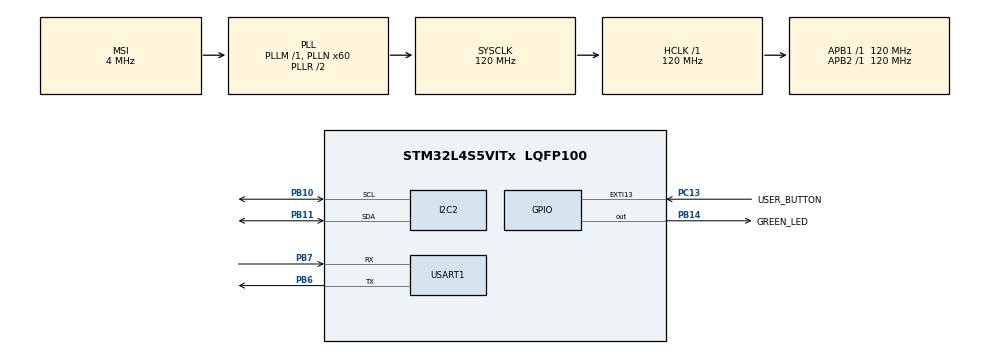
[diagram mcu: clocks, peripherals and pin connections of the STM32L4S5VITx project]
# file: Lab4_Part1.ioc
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Mcu.Family=STM32L4
RCC.MSI_VALUE=4000000
RCC.CortexFreq_Value=120000000
PB10.Mode=I2C
PC13.Signal=GPXTI13
PB14.GPIO_Label=GREEN_LED
I2C2.Timing=0x307075B1
PC13.GPIO_Label=USER_BUTTON
PB11.Signal=I2C2_SDA
RCC.SYSCLKSource=RCC_SYSCLKSOURCE_PLLCLK
ProjectManager.StackSize=0x400
USART1.VirtualMode-Asynchronous=VM_ASYNC
PB11.Mode=I2C
PB3\ (JTDO/TRACESWO).Signal=SYS_JTDO-SWO
ProjectManager.TargetToolchain=STM32CubeIDE
RCC.HCLKFreq_Value=120000000
RCC.APB2TimFreq_Value=120000000
PB6.Signal=USART1_TX
PB6.Mode=Asynchronous
RCC.USBFreq_Value=48000000
RCC.AHBFreq_Value=120000000
PB10.Signal=I2C2_SCL
PB14.Signal=GPIO_Output
RCC.HSE_VALUE=8000000
board=B-L4S5I-IOT01A
RCC.VCOOutputFreq_Value=240000000
RCC.APB2Freq_Value=120000000
VP_TIM2_VS_ClockSourceINT.Mode=Internal
RCC.ADCFreq_Value=48000000
PB7.Signal=USART1_RX
TIM2.Period=12000000
Mcu.Name=STM32L4S5VITx
RCC.SYSCLKFreq_VALUE=120000000
Mcu.Package=LQFP100
PB7.Mode=Asynchronous
ProjectManager.HeapSize=0x200
RCC.HSI_VALUE=16000000
NVIC.PriorityGroup=NVIC_PRIORITYGROUP_4
RCC.PLLN=60
RCC.APB1TimFreq_Value=120000000
RCC.APB1Freq_Value=120000000
RCC.HSI48_VALUE=48000000
PA13\ (JTMS/SWDIO).Signal=SYS_JTMS-SWDIO
RCC.PLLSAI1N=24

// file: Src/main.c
/* USER CODE BEGIN Header */
/**
  ******************************************************************************
  * @file           : main.c
  * @brief          : Main program body
  ******************************************************************************
  * @attention
  *
  * <h2><center>&copy; Copyright (c) 2021 STMicroelectronics.
  * All rights reserved.</center></h2>
  *
  * This software component is licensed by ST under BSD 3-Clause license,
  * the "License"; You may not use this file except in compliance with the
  * License. You may obtain a copy of the License at:
  *                        opensource.org/licenses/BSD-3-Clause
  *
  ******************************************************************************
  */
/* USER CODE END Header */
#include "main.h"

/* USER CODE BEGIN Includes */
#include <stdio.h>
#include <string.h>
#include "stm32l4s5i_iot01_accelero.h"
#include "stm32l4s5i_iot01_gyro.h"
#include "stm32l4s5i_iot01_hsensor.h"
#include "stm32l4s5i_iot01_magneto.h"
#include "stm32l4s5i_iot01_nfctag.h"
#include "stm32l4s5i_iot01_psensor.h"
#include "stm32l4s5i_iot01_tsensor.h"
/* USER CODE END Includes */

I2C_HandleTypeDef hi2c2;

TIM_HandleTypeDef htim2;

UART_HandleTypeDef huart1;

void SystemClock_Config(void);
static void MX_GPIO_Init(void);
static void MX_I2C2_Init(void);
static void MX_USART1_UART_Init(void);
static void MX_TIM2_Init(void);
/* USER CODE BEGIN PFP */
void HAL_GPIO_EXTI_Callback(uint16_t GPIO_Pin);
void HAL_TIM_PeriodElapsedCallback (TIM_HandleTypeDef * htim);
/* USER CODE END PFP */

/* USER CODE BEGIN 0 */
float humidity = 0.0;	// for humidity, HTS221
int16_t pDataXYZ_magneto[3];		// for magnetometer, LIS3MDL
int16_t pDataXYZ_accelero[3];		// for accelerometer, LSM6DSL
float pressure = 0;		// for barometer, LPS22HB

uint8_t str[100];		// store string
int button_counter = 0;	// count button state
int number = 0;			// for sample rate check
int another_number = 0;	// for sample rate check
/* USER CODE END 0 */

int main(void)
{

  /* MCU Configuration--------------------------------------------------------*/

  /* Reset of all peripherals, Initializes the Flash interface and the Systick. */
  HAL_Init();

  /* Configure the system clock */
  SystemClock_Config();

  /* Initialize all configured peripherals */
  MX_GPIO_Init();
  MX_I2C2_Init();
  MX_USART1_UART_Init();
  MX_TIM2_Init();
  /* USER CODE BEGIN 2 */
  // Initialize peripherals
  BSP_HSENSOR_Init();
  BSP_MAGNETO_Init();
  BSP_ACCELERO_Init();
  BSP_PSENSOR_Init();
  HAL_TIM_Base_Start_IT(&htim2);
  /* USER CODE END 2 */

  /* Infinite loop */
  /* USER CODE BEGIN WHILE */
  while (1)
  {
	  // Read value
	  humidity = BSP_HSENSOR_ReadHumidity();	// read humidity
	  BSP_MAGNETO_GetXYZ(pDataXYZ_magneto);		// read magneto
	  BSP_ACCELERO_AccGetXYZ(pDataXYZ_accelero);// read accelero
	  pressure = BSP_PSENSOR_ReadPressure();	// read pressure
	  another_number = number * 2;		// for sample rate testing in SWV timeline graph
	  HAL_Delay(10);	// further adjust sample rate
	  // Print value
	  memset(str,0,100);		// clear str
	  if (button_counter == 0) {
		  sprintf((char*)str, "The humidity reading is %d\n", (int)humidity);	// store string into str
		  HAL_UART_Transmit(&huart1, str, strlen((char*)str), 5);	// display humidity
	  }
	  else if (button_counter == 1) {
		  sprintf((char*)str, "The magnetometer readings are X = %d, Y = %d, Z = %d\n", (int)pDataXYZ_magneto[0], (int)pDataXYZ_magneto[1], (int)pDataXYZ_magneto[2]);	// store string into str
		  HAL_UART_Transmit(&huart1, str, strlen((char*)str), 5);	// display 3-axis magnetometer readings
	  }
	  else if (button_counter == 2) {
		  sprintf((char*)str, "The accelerometer readings are X = %d, Y = %d, Z = %d\n", (int)pDataXYZ_accelero[0], (int)pDataXYZ_accelero[1], (int)pDataXYZ_accelero[2]);	// store string into str
		  HAL_UART_Transmit(&huart1, str, strlen((char*)str), 5);	// display 3D accelerometer readings
	  }
	  else if (button_counter == 3) {
		  sprintf((char*)str, "The barometer reading is %d\n", (int)pressure);	// store string into str
		  HAL_UART_Transmit(&huart1, str, strlen((char*)str), 5);	// display pressure
	  }
    /* USER CODE END WHILE */

  }
}

void SystemClock_Config(void)
{
  RCC_OscInitTypeDef RCC_OscInitStruct = {0};
  RCC_ClkInitTypeDef RCC_ClkInitStruct = {0};
  RCC_PeriphCLKInitTypeDef PeriphClkInit = {0};

  /** Configure the main internal regulator output voltage
  */
  if (HAL_PWREx_ControlVoltageScaling(PWR_REGULATOR_VOLTAGE_SCALE1_BOOST) != HAL_OK)
  {
    Error_Handler();
  }
  /** Initializes the RCC Oscillators according to the specified parameters
  * in the RCC_OscInitTypeDef structure.
  */
  RCC_OscInitStruct.OscillatorType = RCC_OSCILLATORTYPE_MSI;
  RCC_OscInitStruct.MSIState = RCC_MSI_ON;
  RCC_OscInitStruct.MSICalibrationValue = 0;
  RCC_OscInitStruct.MSIClockRange = RCC_MSIRANGE_6;
  RCC_OscInitStruct.PLL.PLLState = RCC_PLL_ON;
  RCC_OscInitStruct.PLL.PLLSource = RCC_PLLSOURCE_MSI;
  RCC_OscInitStruct.PLL.PLLM = 1;
  RCC_OscInitStruct.PLL.PLLN = 60;
  RCC_OscInitStruct.PLL.PLLP = RCC_PLLP_DIV2;
  RCC_OscInitStruct.PLL.PLLQ = RCC_PLLQ_DIV2;
  RCC_OscInitStruct.PLL.PLLR = RCC_PLLR_DIV2;
  if (HAL_RCC_OscConfig(&RCC_OscInitStruct) != HAL_OK)
  {
    Error_Handler();
  }
  /** Initializes the CPU, AHB and APB buses clocks
  */
  RCC_ClkInitStruct.ClockType = RCC_CLOCKTYPE_HCLK|RCC_CLOCKTYPE_SYSCLK
                              |RCC_CLOCKTYPE_PCLK1|RCC_CLOCKTYPE_PCLK2;
  RCC_ClkInitStruct.SYSCLKSource = RCC_SYSCLKSOURCE_PLLCLK;
  RCC_ClkInitStruct.AHBCLKDivider = RCC_SYSCLK_DIV1;
  RCC_ClkInitStruct.APB1CLKDivider = RCC_HCLK_DIV1;
  RCC_ClkInitStruct.APB2CLKDivider = RCC_HCLK_DIV1;

  if (HAL_RCC_ClockConfig(&RCC_ClkInitStruct, FLASH_LATENCY_5) != HAL_OK)
  {
    Error_Handler();
  }
  PeriphClkInit.PeriphClockSelection = RCC_PERIPHCLK_USART1|RCC_PERIPHCLK_I2C2;
  PeriphClkInit.Usart1ClockSelection = RCC_USART1CLKSOURCE_PCLK2;
  PeriphClkInit.I2c2ClockSelection = RCC_I2C2CLKSOURCE_PCLK1;
  if (HAL_RCCEx_PeriphCLKConfig(&PeriphClkInit) != HAL_OK)
  {
    Error_Handler();
  }
}

static void MX_I2C2_Init(void)
{

  hi2c2.Instance = I2C2;
  hi2c2.Init.Timing = 0x307075B1;
  hi2c2.Init.OwnAddress1 = 0;
  hi2c2.Init.AddressingMode = I2C_ADDRESSINGMODE_7BIT;
  hi2c2.Init.DualAddressMode = I2C_DUALADDRESS_DISABLE;
  hi2c2.Init.OwnAddress2 = 0;
  hi2c2.Init.OwnAddress2Masks = I2C_OA2_NOMASK;
  hi2c2.Init.GeneralCallMode = I2C_GENERALCALL_DISABLE;
  hi2c2.Init.NoStretchMode = I2C_NOSTRETCH_DISABLE;
  if (HAL_I2C_Init(&hi2c2) != HAL_OK)
  {
    Error_Handler();
  }
  /** Configure Analogue filter
  */
  if (HAL_I2CEx_ConfigAnalogFilter(&hi2c2, I2C_ANALOGFILTER_ENABLE) != HAL_OK)
  {
    Error_Handler();
  }
  /** Configure Digital filter
  */
  if (HAL_I2CEx_ConfigDigitalFilter(&hi2c2, 0) != HAL_OK)
  {
    Error_Handler();
  }

}

static void MX_TIM2_Init(void)
{

  TIM_ClockConfigTypeDef sClockSourceConfig = {0};
  TIM_MasterConfigTypeDef sMasterConfig = {0};

  htim2.Instance = TIM2;
  htim2.Init.Prescaler = 0;
  htim2.Init.CounterMode = TIM_COUNTERMODE_UP;
  htim2.Init.Period = 12000000;
  htim2.Init.ClockDivision = TIM_CLOCKDIVISION_DIV1;
  htim2.Init.AutoReloadPreload = TIM_AUTORELOAD_PRELOAD_DISABLE;
  if (HAL_TIM_Base_Init(&htim2) != HAL_OK)
  {
    Error_Handler();
  }
  sClockSourceConfig.ClockSource = TIM_CLOCKSOURCE_INTERNAL;
  if (HAL_TIM_ConfigClockSource(&htim2, &sClockSourceConfig) != HAL_OK)
  {
    Error_Handler();
  }
  sMasterConfig.MasterOutputTrigger = TIM_TRGO_UPDATE;
  sMasterConfig.MasterSlaveMode = TIM_MASTERSLAVEMODE_DISABLE;
  if (HAL_TIMEx_MasterConfigSynchronization(&htim2, &sMasterConfig) != HAL_OK)
  {
    Error_Handler();
  }

}

static void MX_USART1_UART_Init(void)
{

  huart1.Instance = USART1;
  huart1.Init.BaudRate = 115200;
  huart1.Init.WordLength = UART_WORDLENGTH_8B;
  huart1.Init.StopBits = UART_STOPBITS_1;
  huart1.Init.Parity = UART_PARITY_NONE;
  huart1.Init.Mode = UART_MODE_TX_RX;
  huart1.Init.HwFlowCtl = UART_HWCONTROL_NONE;
  huart1.Init.OverSampling = UART_OVERSAMPLING_16;
  huart1.Init.OneBitSampling = UART_ONE_BIT_SAMPLE_DISABLE;
  huart1.Init.ClockPrescaler = UART_PRESCALER_DIV1;
  huart1.AdvancedInit.AdvFeatureInit = UART_ADVFEATURE_NO_INIT;
  if (HAL_UART_Init(&huart1) != HAL_OK)
  {
    Error_Handler();
  }
  if (HAL_UARTEx_SetTxFifoThreshold(&huart1, UART_TXFIFO_THRESHOLD_1_8) != HAL_OK)
  {
    Error_Handler();
  }
  if (HAL_UARTEx_SetRxFifoThreshold(&huart1, UART_RXFIFO_THRESHOLD_1_8) != HAL_OK)
  {
    Error_Handler();
  }
  if (HAL_UARTEx_DisableFifoMode(&huart1) != HAL_OK)
  {
    Error_Handler();
  }

}

static void MX_GPIO_Init(void)
{
  GPIO_InitTypeDef GPIO_InitStruct = {0};

  /* GPIO Ports Clock Enable */
  __HAL_RCC_GPIOE_CLK_ENABLE();
  __HAL_RCC_GPIOC_CLK_ENABLE();
  __HAL_RCC_GPIOB_CLK_ENABLE();
  __HAL_RCC_GPIOA_CLK_ENABLE();

  /*Configure GPIO pin Output Level */
  HAL_GPIO_WritePin(RED_LED_GPIO_Port, RED_LED_Pin, GPIO_PIN_RESET);

  /*Configure GPIO pin Output Level */
  HAL_GPIO_WritePin(GREEN_LED_GPIO_Port, GREEN_LED_Pin, GPIO_PIN_RESET);

  /*Configure GPIO pin : RED_LED_Pin */
  GPIO_InitStruct.Pin = RED_LED_Pin;
  GPIO_InitStruct.Mode = GPIO_MODE_OUTPUT_PP;
  GPIO_InitStruct.Pull = GPIO_NOPULL;
  GPIO_InitStruct.Speed = GPIO_SPEED_FREQ_LOW;
  HAL_GPIO_Init(RED_LED_GPIO_Port, &GPIO_InitStruct);

  /*Configure GPIO pin : USER_BUTTON_Pin */
  GPIO_InitStruct.Pin = USER_BUTTON_Pin;
  GPIO_InitStruct.Mode = GPIO_MODE_IT_RISING;
  GPIO_InitStruct.Pull = GPIO_NOPULL;
  HAL_GPIO_Init(USER_BUTTON_GPIO_Port, &GPIO_InitStruct);

  /*Configure GPIO pin : GREEN_LED_Pin */
  GPIO_InitStruct.Pin = GREEN_LED_Pin;
  GPIO_InitStruct.Mode = GPIO_MODE_OUTPUT_PP;
  GPIO_InitStruct.Pull = GPIO_NOPULL;
  GPIO_InitStruct.Speed = GPIO_SPEED_FREQ_LOW;
  HAL_GPIO_Init(GREEN_LED_GPIO_Port, &GPIO_InitStruct);

  /* EXTI interrupt init*/
  HAL_NVIC_SetPriority(EXTI15_10_IRQn, 0, 0);
  HAL_NVIC_EnableIRQ(EXTI15_10_IRQn);

}

/* USER CODE BEGIN 4 */
void HAL_GPIO_EXTI_Callback(uint16_t GPIO_Pin) {	// detect when the button is pressed
	if (GPIO_Pin == USER_BUTTON_Pin) {
		HAL_GPIO_TogglePin(GREEN_LED_GPIO_Port, GREEN_LED_Pin);
		button_counter++;
		if (button_counter == 4) {
			button_counter = 0;
		}
	}
}

void HAL_TIM_PeriodElapsedCallback(TIM_HandleTypeDef * htim) {	// What happens when timer reaches its counter number
	if (htim == &htim2) {
		number++;
		if (number == 10) {
			number = 0;
		}
	}
}
/* USER CODE END 4 */

void Error_Handler(void)
{
  __disable_irq();
  while (1)
  {
  }
}

/************************ (C) COPYRIGHT STMicroelectronics *****END OF FILE****/
